# A31G34x register map
Vendor: VENDOR ABOV Semiconductor Co., Ltd.; Series: A31G34x; File version: 1.0
CPU: CM0+ r0p1, little endian, no MPU, no FPU, VTOR, 2 interrupt priority bits
Registers are 32-bit, read-only, no defined reset value unless marked. A register's access mark holds for its fields unless they carry their own. Offsets are from the block's base; [hi:lo] are bit positions.

## TS — Temperature Sensor
Base 0x40005F80
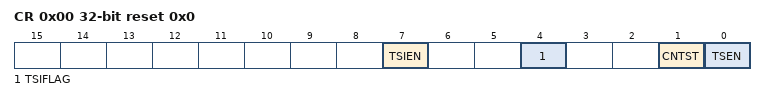
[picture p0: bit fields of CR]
0x00 CR rw reset 0x0 — Temperature Sensor Control Register
  [7] TSIEN — Temperature Sensor Interrupt Enable
    0=Disable interrupt; 1=Enable interrupt
  [4] TSIFLAG — Temperature Sensor Interrupt flag
    0=No request occurred; 1=Request occurred. This bit is cleared to '0' when write '1'.
  [1] CNTST — Counting Start
    0=Stop counting; 1=Start (Counting start after 'reload data to TS_ICNT and clear TS_OUTDR'.)
  [0] TSEN — Temperature Sensor Enable
    0=Disable temperature sensor; 1=Enable temperature sensor
0x04 IDR rw reset 0xFFFFF — Temperature Sensor Interval Data Register
  [19:0] IDATA — Temperature Sensor Interval Data
0x08 ICNTR reset 0xFFFF — Temperature Sensor Interval Counter Register
  [19:0] ICNT — Temperature Sensor Interval Counter
0x0C OUTDR reset 0x0 — Temperature Sensor Output Data Register
  [23:0] OUTDATA — Temperature Sensor Output Data

## WDT — Watch-Dog Timer
Base 0x40001A00
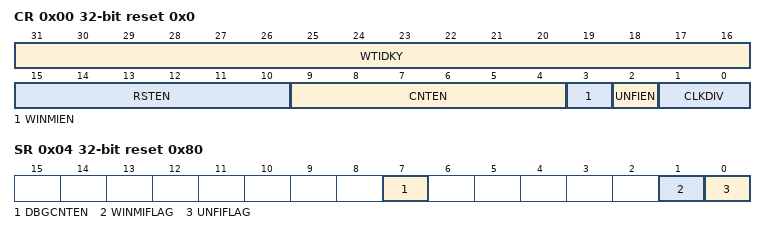
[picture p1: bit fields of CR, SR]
0x00 CR rw reset 0x0 — Watch-Dog Timer Control Register
  [31:16] WTIDKY wo — Write Identification Key (0x5a69)
    0x5A69=Value (Key Value (0x5a69))
  [15:10] RSTEN — Watch-Dog Timer Reset Enable
    37=Disable Watch-Dog Timer reset. (0x25); 0=Enable Watch-Dog Timer reset
  [9:4] CNTEN — Watch-Dog Timer Counter Enable
    26=Disable Watch-Dog Timer counter. (0x1a); 0=Enable Watch-Dog Timer counter
  [3] WINMIEN — Watch-Dog Timer Window Match Interrupt Enable
    0=Disable window data match interrupt; 1=Enable window data match interrupt
  [2] UNFIEN — Watch-Dog Timer Underflow Interrupt Enable
    0=Disable Watch-Dog Timer underflow interrupt; 1=Enable Watch-Dog Timer underflow interrupt
  [1:0] CLKDIV — Watch-Dog Timer Clock Divider
    0=fWDT4; 1=fWDT16; 2=fWDT64; 3=fWDT256
0x04 SR rw reset 0x80 — Watch-Dog Timer Status Register
  [7] DBGCNTEN — Watch-Dog Timer Counter Enable When the core is halted in debug mode
    0=Run (The Watch-Dog Timer counter continues even if the core is halted); 1=Stop (The Watch-Dog Timer counter is stopped when the core is halted)
  [1] WINMIFLAG — Watch-Dog Timer Window Match Interrupt Flag
    0=No request occurred; 1=Request occurred
  [0] UNFIFLAG — Watch-Dog Timer Underflow Interrupt Flag
    0=No request occurred; 1=Request occurred
0x08 DR rw reset 0xFFF — Watch-Dog Timer Data Register
  [23:0] DATA — Watch-Dog Timer Data
0x0C CNT reset 0xFFF — Watch-Dog Timer Counter Register
  [23:0] CNT — Watch-Dog Timer Counter
0x10 WINDR rw reset 0x1FFF — Watch-Dog Timer Window Data Register
  [23:0] WDATA — Watch-Dog Timer Window Data
0x14 CNTR wo reset 0x0 — Watch-Dog Timer Counter Reload Register
  [7:0] CNTR — Watch-Dog Timer Counter Reload
    106=Reload the WDTDR value to Watch-Dog Timer counter and re-start; 0=NoEffect

## RTCC — Real Time Clock and Calendar
Base 0x40005200
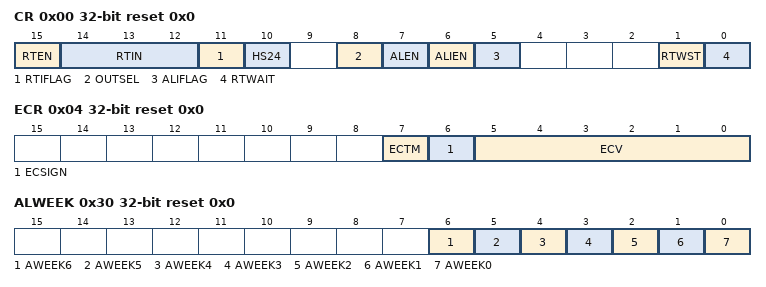
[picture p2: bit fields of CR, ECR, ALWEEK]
0x00 CR rw reset 0x0 — RTCC Control Register
  [15] RTEN — RTCC Enable
  [14:12] RTIN — RTCC Interrupt Interval Selection
  [11] RTIFLAG — RTCC Interval Interrupt Flag
  [10] HS24 — 12/24-hour System Selection
  [8] OUTSEL — RTCOUT Selection
  [7] ALEN — RTCC Alarm Match Operation Enable
  [6] ALIEN — RTCC Alarm Match Interrupt Enable
  [5] ALIFLAG — RTCC Alarm Match Interrupt Flag
  [1] RTWST ro — RTCC Wait Status Flag
  [0] RTWAIT — RTCC Wait Control
0x04 ECR rw reset 0x0 — RTCC Time Error Correcton Register
  [7] ECTM — Time Error Correction Timing Selection
  [6] ECSIGN — Time Error Correction Data Sign
  [5:0] ECV — Time Error Correction Data
0x08 SCNT reset 0x0 — RTCC Sub-counter Register
  [15:0] RTCNT — RTCC Sub-counter
0x0C SEC rw reset 0x0 — RTCC Second Counter Register
  [6:0] RSEC — RTCC Second Counter
0x10 MIN rw reset 0x0 — RTCC Minute Counter Register
  [6:0] RMIN — RTCC Minute Counter
0x14 HOUR rw reset 0x12 — RTCC Hour Counter Register
  [6:0] RHOUR — RTCC Hour Counter
0x18 DAY rw reset 0x1 — RTCC Day Counter Register
  [5:0] RDAY — RTCC Day Counter
0x1C WEEK rw reset 0x0 — RTCC Week Counter Register
  [2:0] RWEEK — RTCC Week Counter
0x20 MONTH rw reset 0x1 — RTCC Month Counter Register
  [4:0] RMONTH — RTCC Month Counter
0x24 YEAR rw reset 0x0 — RTCC Year Counter Register
  [7:0] RYEAR — RTCC Year Counter
0x28 ALMIN rw reset 0x0 — RTCC Alarm Minute Counter Register
  [6:0] AMIN — RTCC Alarm Minute Counter
0x2C ALHOUR rw reset 0x12 — RTCC Alarm Hour Counter Register
  [5:0] AHOUR — RTCC Alarm Hour Counter
0x30 ALWEEK rw reset 0x0 — RTCC Alarm Week Counter Register
  [6] AWEEK6 — Saturday Alarm Setting
  [5] AWEEK5 — Friday Alarm Setting
  [4] AWEEK4 — Thursday Alarm Setting
  [3] AWEEK3 — Wednesday Alarm Setting
  [2] AWEEK2 — Tuesday Alarm Setting
  [1] AWEEK1 — Monday Alarm Setting
  [0] AWEEK0 — Sunday Alarm Setting
